# HDSC_HC32F480 register map
Vendor: HDSC Co.Ltd; Series: ARMCM4; File version: 1.2
CPU: CM0 r0p0, little endian, no MPU, no FPU, 3 interrupt priority bits
Registers are 16-bit, read-write, reset 0x0 unless marked. A register's access mark holds for its fields unless they carry their own. Offsets are from the block's base; lines under a group give offsets from that group; [hi:lo] are bit positions; {n}, {i} and the like mark numbered series; 'fields as' and 'values as' point back to an identical list; <NAME> marks a mode.

## Memory map
0x00000400 ICG size 0x40
0x40008000 AES size 0x48
0x40008400 HASH size 0x80
0x40008800 CRC size 0x100
0x40008800 TRNG size 0x90
0x40010000 EFMD size 0x19
0x40010400 EFM size 0x10C
0x40010800 AOS size 0x174
0x40010C00 SDIOC size 0x50
0x40015000 TMR20 size 0x24 — desc TMR2
0x40015400 TMR21 size 0x24 — desc TMR2
0x40015800 TMR22 size 0x24 — desc TMR2
0x40015C00 TMR23 size 0x24 — desc TMR2
0x40016000 CAN_0 size 0xCA
{0x40009000+0x400*n} TMR{n} size 0x3F6 (n=60..69) — desc TMR6
0x4001BC00 EMB size 0xB8
0x4001C000 SPI size 0x3E
0x4001F400 USART0 size 0xD — desc USART
0x4001F800 USART1 size 0xD — desc USART
0x4001FC00 USART2 size 0xD — desc USART
0x40020000 USART3 size 0xD — desc USART
0x40020400 USART4 size 0xD — desc USART
0x40020800 USART5 size 0xD — desc USART
0x40020C00 USART6 size 0xD — desc USART
0x40021000 MSC0_I2C size 0x1E — desc MSC_I2C
0x40021000 MSC0_SCI size 0x52 — desc MSC_SCI
0x40021000 MSC0_SPI size 0x42 — desc MSC_SPI
0x40021100 MSC1_I2C size 0x1E — desc MSC_I2C
0x40021100 MSC1_SCI size 0x52 — desc MSC_SCI
0x40021100 MSC1_SPI size 0x42 — desc MSC_SPI
0x40021200 MSC2_I2C size 0x1E — desc MSC_I2C
0x40021200 MSC2_SCI size 0x52 — desc MSC_SCI
0x40021200 MSC2_SPI size 0x42 — desc MSC_SPI
0x40021400 CAN_1 size 0xCA
0x40024000 TMR00 size 0x18 — desc TMR0
0x40024400 TMR01 size 0x18 — desc TMR0
0x40024800 TMR40 size 0x30C31 — desc TMR4
0x40024C00 TMR41 size 0x30C31 — desc TMR4
0x40040000 ADC0 size 0xC4 — desc ADC
0x40040400 ADC1 size 0xC4 — desc ADC
0x40040800 ADC2 size 0xB2
0x40041000 DAC size 0x1E
0x40048000 MSTP size 0x16
0x40048400 FCM size 0x21
0x40049000 WDT size 0xA
0x40049400 SWDT size 0xA
0x4004A000 CMP size 0x35
0x4004B400 I2C size 0x39
0x4004B800 VBAT size 0x100
0x4004BA00 RTC size 0x5D
0x40050000 ETH size 0x11058
0x40050000 EXMC size 0x480B8180
0x40050800 SRAMC size 0x11
0x40051000 INTC size 0x25A
0x40052000 DCU0 size 0x1A
0x40052400 DCU1 size 0x1A
0x40052800 DCU2 size 0x1A
0x40052C00 DCU3 size 0x1A
0x40053000 DMAC size 0x21E
0x40053800 PORT size 0x5D4
0x40054000 SYSREG size 0xE2
0x40055000 SMI size 0x9
0x40080000 USH size 0xE02
0x400C0000 USF size 0xE02
0x98000000 QSPI size 0x808
0xE0042000 DBGC size 0x25

## ADC0 — desc ADC
Base 0x40040000
Same registers: ADC1 0x40040400
0x00 STR 8-bit
  [0] STRT
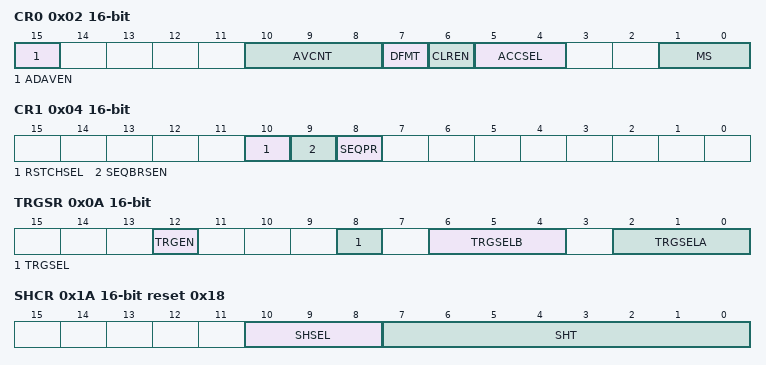
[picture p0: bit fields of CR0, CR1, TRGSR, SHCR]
0x02 CR0
  [15] ADAVEN, [10:8] AVCNT, [7] DFMT, [6] CLREN, [5:4] ACCSEL, [1:0] MS
0x04 CR1
  [10] RSTCHSEL, [9] SEQBRSEN, [8] SEQPR
0x0A TRGSR
  [12] TRGEN, [8] TRGSEL, [6:4] TRGSELB, [2:0] TRGSELA
0x0C CHSELRA 8-bit
  [4:0] CHSELA
0x10 CHSELRB 8-bit
  [4:0] CHSELB
0x14 AVCHSELR 8-bit
  [4:0] AVCHSEL
0x1A SHCR reset 0x18
  [10:8] SHSEL, [7:0] SHT
{0x20+i} SSTR{i} 8-bit reset 0xB (i=0..4)
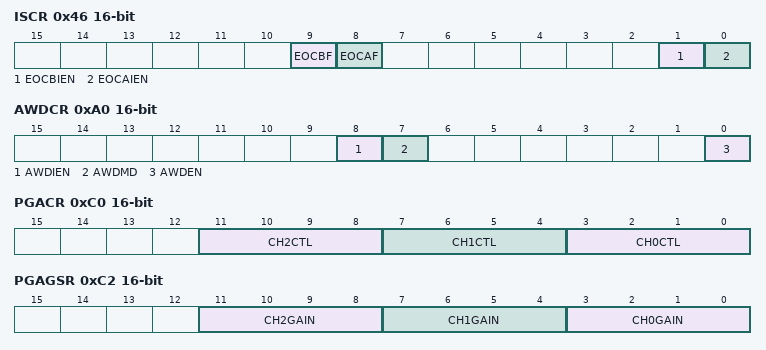
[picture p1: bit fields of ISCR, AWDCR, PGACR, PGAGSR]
0x46 ISCR
  [9] EOCBF, [8] EOCAF, [1] EOCBIEN, [0] EOCAIEN
{0x50+2i} DR{i} ro (i=0..4)
0xA0 AWDCR
  [8] AWDIEN, [7] AWDMD, [0] AWDEN
0xA4 AWDDR0
0xA6 AWDDR1
0xA8 AWDCNDSR 8-bit
  [4:0] AWDCND
0xAC AWDCHSR 8-bit
  [4:0] AWDCH
0xB0 AWDSR 8-bit
  [4:0] AWDF
0xC0 PGACR
  [11:8] CH2CTL, [7:4] CH1CTL, [3:0] CH0CTL
0xC2 PGAGSR
  [11:8] CH2GAIN, [7:4] CH1GAIN, [3:0] CH0GAIN

## ADC2
Base 0x40040800
Registers as ADC0, without SHCR, PGACR, PGAGSR; these are added or differ:
0x0C CHSELRA
  [11:0] CHSELA
0x10 CHSELRB
  [11:0] CHSELB
0x14 AVCHSELR
  [11:0] AVCHSEL
{0x20+i} SSTR{i} 8-bit reset 0xB (i=5..11)
{0x50+2i} DR{i} ro (i=5..11)
0xA8 AWDCNDSR
  [11:0] AWDCND
0xAC AWDCHSR
  [11:0] AWDCH
0xB0 AWDSR
  [11:0] AWDF

## AES
Base 0x40008000
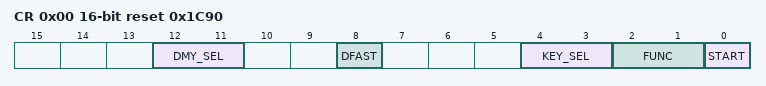
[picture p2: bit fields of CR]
0x00 CR reset 0x1C90
  [12:11] DMY_SEL, [8] DFAST ro, [4:3] KEY_SEL, [2:1] FUNC, [0] START
{0x10+4i} DR{i} 32-bit (i=0..3)
{0x20+4i} KR{i} 32-bit (i=0..7)
0x40 RR0 32-bit
0x44 RR1 32-bit
